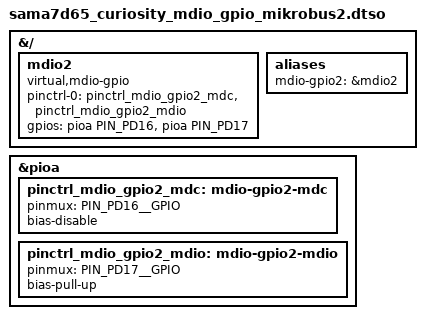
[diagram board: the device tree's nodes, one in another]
/*
 * Device Tree overlay for MDIO Bitbang using GPIO
 * on SAMA7D65 Curiosity Kit MikroBus 2 RX (MDIO) and TX (MDC)
 *
 * Copyright (C) 2026 Microchip Technology, Inc.
 * Author: Joemel John A. Diente <JoemelJohn.Diente@microchip.com>
 */

 /*
  * J26 MikroBus 2 Pinout
  * AN - AD8 - MBUS2_AN_PC13
  * RST - nRST_MBUS
  * CS - FLEXCOM4_IO4 - MBUS2_SPI_CS_PA14
  * SCK - FLEXCOM4_IO2 - MBUS2_SPI_SCK_PA16
  * MISO - FLEXCOM4_IO1 - MBUS2_SPI_MISO_PA17
  * MOSI - FLEXCOM4_IO0 - MBUS2_SPI_MOSI_PA18
  * ====
  * PWM - PMWL1 - MBUS2_PWM_PB17
  * INT - - MBUS2_INT_PA22 (Pull-up 110k)
  * RX - FLEXCOM5_IO1 - MBUS2_RX/CAN4_RX_PD17 (GPIO - MDIO2)
  * TX - FLEXCOM5_IO0 - MBUS2_TX/CAN4_TX_PD16 (GPIO - MDC2)
  * SCL - FLEXCOM0_IO1 - MBUS2_TWCK_PC6
  * SDA - FLEXCOM0_IO0 - MBUS2_TWD_PC7
  */

/dts-v1/;
/plugin/;

#include "sama7d65-pinfunc.h"
#include "dt-bindings/gpio/gpio.h"

&{/} {

	mdio2: mdio2 {
		compatible = "virtual,mdio-gpio";
		#address-cells = <1>;
		#size-cells = <0>;
		pinctrl-names = "default";
		pinctrl-0 = <&pinctrl_mdio_gpio2_mdc &pinctrl_mdio_gpio2_mdio>;
		gpios = <&pioa PIN_PD16 GPIO_ACTIVE_HIGH>,	/* MDC */
			<&pioa PIN_PD17 GPIO_ACTIVE_HIGH>;	/* MDIO */
	};

	aliases {
		mdio-gpio2 = &mdio2;
	};
};

&pioa {

	pinctrl_mdio_gpio2_mdc: mdio-gpio2-mdc {
		pinmux = <PIN_PD16__GPIO>;
		bias-disable;
	};

	pinctrl_mdio_gpio2_mdio: mdio-gpio2-mdio {
		pinmux = <PIN_PD17__GPIO>;
		bias-pull-up;
	};
};
